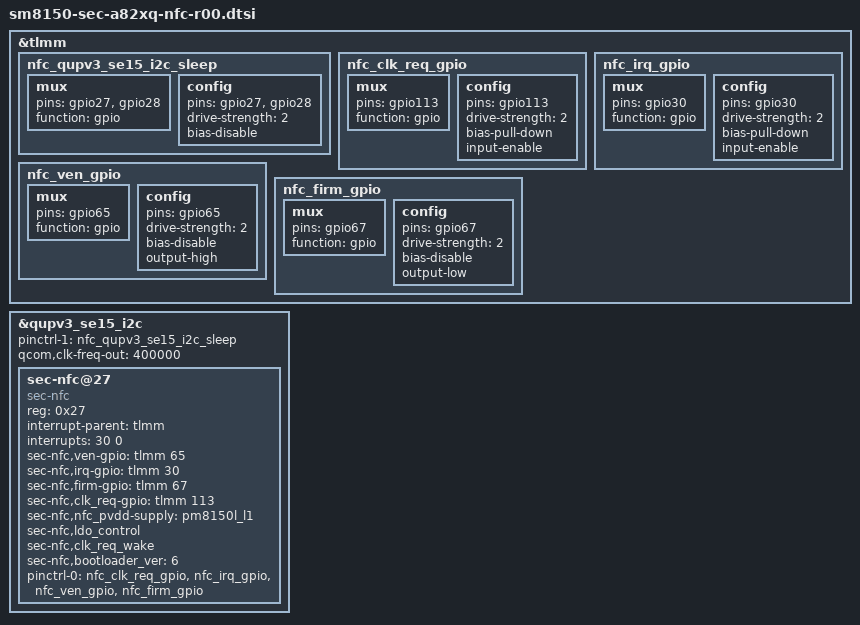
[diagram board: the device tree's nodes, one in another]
/*
 * This program is free software; you can redistribute it and/or modify
 * it under the terms of the GNU General Public License version 2 and
 * only version 2 as published by the Free Software Foundation.
 *
 * This program is distributed in the hope that it will be useful,
 * but WITHOUT ANY WARRANTY; without even the implied warranty of
 * MERCHANTABILITY or FITNESS FOR A PARTICULAR PURPOSE.  See the
 * GNU General Public License for more details.
 */
&tlmm {
	nfc_qupv3_se15_i2c_sleep: nfc_qupv3_se15_i2c_sleep {
	      mux {
		      pins = "gpio27", "gpio28";
		      function = "gpio";
	      };

	      config {
		      pins = "gpio27", "gpio28";
		      drive-strength = <2>;
		      bias-disable;
	      };
	};

	nfc_clk_req_gpio: nfc_clk_req_gpio {
		mux {
			pins = "gpio113";
			function = "gpio";
		};

		config {
			pins = "gpio113";
			drive-strength = <2>;
			bias-pull-down;
			input-enable;
		};
	};

	nfc_irq_gpio: nfc_irq_gpio {
		mux {
			pins = "gpio30";
			function = "gpio";
		};
		config {
			pins = "gpio30";
			drive-strength = <2>;
			bias-pull-down;
			input-enable;
		};
	};

	nfc_ven_gpio: nfc_ven_gpio {
		mux {
			pins = "gpio65";
			function = "gpio";
		};
		config {
			pins = "gpio65";
			drive-strength = <2>;
			bias-disable;
			output-high;
		};
	};

	nfc_firm_gpio: nfc_firm_gpio {
		mux {
			pins = "gpio67";
			function = "gpio";
		};
		config {
			pins = "gpio67";
			drive-strength = <2>;
			bias-disable;
			output-low;
		};
	};
};

/* gpio27 and gpio28 are used for nfc i2c */
&qupv3_se15_i2c {
	status = "okay";
	pinctrl-1 = <&nfc_qupv3_se15_i2c_sleep>;
	qcom,clk-freq-out = <400000>;
	sec-nfc@27 {
		compatible = "sec-nfc";
		reg = <0x27>;
		interrupt-parent = <&tlmm>;
		interrupts = <30 0>;

		sec-nfc,ven-gpio = <&tlmm 65 0>;
		sec-nfc,irq-gpio = <&tlmm 30 0>;
		sec-nfc,firm-gpio = <&tlmm 67 0>;
		sec-nfc,clk_req-gpio = <&tlmm 113 0>;
		sec-nfc,nfc_pvdd-supply = <&pm8150l_l1>;
		sec-nfc,ldo_control;
		sec-nfc,clk_req_wake;
		sec-nfc,bootloader_ver = <6>;

		pinctrl-names = "default";
		pinctrl-0 = <&nfc_clk_req_gpio &nfc_irq_gpio &nfc_ven_gpio &nfc_firm_gpio>;
	};
};
